# psoc4200m register map
Vendor: Cypress Semiconductor; Series: PSoC4200M; File version: 1.0
CPU: CM0 r0p1, little endian, no MPU, no FPU, 2 interrupt priority bits
Registers are 32-bit, read-write, reset 0x0 unless marked. A register's access mark holds for its fields unless they carry their own. Offsets are from the block's base; [hi:lo] are bit positions; {n}, {i} and the like mark numbered series.

## CSD0 — Capsense Controller
Base 0x40280000
Same registers: CSD1 0x40290000
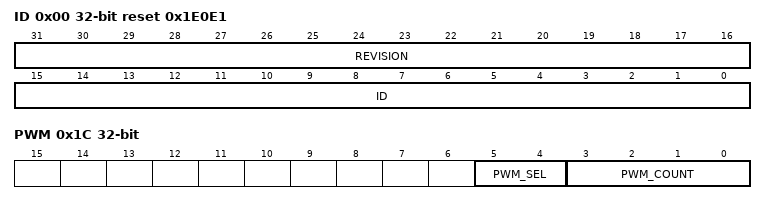
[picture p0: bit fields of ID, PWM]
0x00 ID ro reset 0x1E0E1 — ID & Revision Number
  [31:16] REVISION — the version number is 0x0001
  [15:0] ID — the ID of CSD peripheral is 0xE0E1
0x14 INTR — CSD Interrupt Request Register
  [0] CSD — The CSD IRQ bit is set. Firmware must clear this bit as part of the interrupt handler.
0x18 INTR_SET — CSD Interrupt set register
  [0] CSD — Write with '1' to set corresponding bit in interrupt request register.
0x1C PWM — CSD PWM Register
  [5:4] PWM_SEL — The mode of the PWM modulator
    0=OFF (The PWM modulator is OFF and has no effect); 2=FIXED_HIGH (The PWM modulator changes the low phase of csd_sense to a fixed length (used for negative charge transfer).); 3=FIXED_LOW (The PWM modulator changes the high phase of csd_sense to a fixed length (used for positive charge transfer).)
  [3:0] PWM_COUNT — The length of the modulation pulse in clk_csd2 cycles.

## LCD — LCD Controller Block
Base 0x402A0000
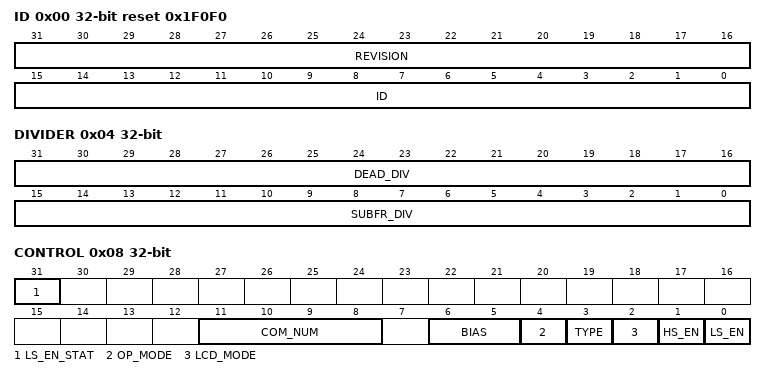
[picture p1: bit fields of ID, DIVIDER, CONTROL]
0x00 ID ro reset 0x1F0F0 — ID & Revision
  [31:16] REVISION — the version number is 0x0001
  [15:0] ID — the ID of LCD controller peripheral is 0xF0F0
0x04 DIVIDER — LCD Divider Register
  [31:16] DEAD_DIV — Length of the dead time period in cycles. When set to zero, no dead time period exists.
  [15:0] SUBFR_DIV — Input clock frequency divide value, to generate the 1/4 sub-frame period. The sub-frame period is 4*(SUBFR_DIV+1) cycles long.
0x08 CONTROL — LCD Configuration Register
  [31] LS_EN_STAT ro — LS enable status bit. This bit is a copy of LS_EN that is synchronized to the low speed clock domain and back to the system clock domain. Firmware can use this bit to observe whether LS_EN has taken effect in the low speed clock domain. Firmware should never change the configuration for the LS generator without ensuring this bit is 0. The following procedure should be followed to disable the LS generator: 1. If LS_EN=0 we are done. Exit the procedure. 2. Check that LS_EN_STAT=1. If not, wait until it is. This will catch the case of a recent enable (LS_EN=1) that has not taken effect yet. 3. Set LS_EN=0. 4. Wait until LS_EN_STAT=0.
  [11:8] COM_NUM — The number of COM connections minus 2. So: 0: 2 COM's 1: 3 COM's ... 13: 15 COM's 14: 16 COM's 15: undefined
  [6:5] BIAS — PWM bias selection
    0=HALF (1/2 Bias); 1=THIRD (1/3 Bias); 2=FOURTH (1/4 Bias (not supported by LS generator)); 3=FIFTH (1/5 Bias (not supported by LS generator))
  [4] OP_MODE — Driving mode configuration
    0=PWM (PWM Mode); 1=CORRELATION (Digital Correlation Mode)
  [3] TYPE — LCD driving waveform type configuration.
    0=TYPE_A (Type A - Each frame addresses each COM pin only once with a balanced (DC=0) waveform.); 1=TYPE_B (Type B - Each frame addresses each COM pin twice in sequence with a positive and negative waveform that together are balanced (DC=0).)
  [2] LCD_MODE — HS/LS Mode selection
    0=LS (Select Low Speed (32kHz) Generator (Works in Active, Sleep and DeepSleep power modes).); 1=HS (Select High Speed (system clock) Generator (Works in Active and Sleep power modes only).)
  [1] HS_EN — High speed (HS) generator enable 1: enable 0: disable
  [0] LS_EN — Low speed (LS) generator enable 1: enable 0: disable
{0x100+4i} DATA0[{i}] (i=0..7) — LCD Pin Data Registers
  [31:0] DATA — Bits [4i+3:4i] represent the pin data for pin [i] for COMS 1-4 (COM1 is lsb).
{0x200+4i} DATA1[{i}] (i=0..7) — LCD Pin Data Registers
  [31:0] DATA — Bits [4i+3:4i] represent the pin data for pin [i] for COMS 5-8 (COM5 is lsb).
{0x300+4i} DATA2[{i}] (i=0..7) — LCD Pin Data Registers
  [31:0] DATA — Bits [4i+3:4i] represent the pin data for pin [i] for COMS 9-12 (COM9 is lsb).
{0x400+4i} DATA3[{i}] (i=0..7) — LCD Pin Data Registers
  [31:0] DATA — Bits [4i+3:4i] represent the pin data for pin [i] for COMS 13-16 (COM13 is lsb).

## Notices in the file
Copyright 2016-2020 Cypress Semiconductor Corporation
SPDX-License-Identifier: Apache-2.0
Licensed under the Apache License, Version 2.0 (the "License");
you may not use this file except in compliance with the License.
You may obtain a copy of the License at
http://www.apache.org/licenses/LICENSE-2.0
Unless required by applicable law or agreed to in writing, software
distributed under the License is distributed on an "AS IS" BASIS,
WITHOUT WARRANTIES OR CONDITIONS OF ANY KIND, either express or implied.
See the License for the specific language governing permissions and
limitations under the License.
